VERSION ""

NS_ :

BS_:

BU_:
VAL_TABLE_ VT_PTO_req 1 "Engage_RPTO" 0 "Disengage_RPTO" ;
VAL_TABLE_ VT_MFD_req 1 "FWD_Engaged" 0 "FWD_Disengaged" ;
VAL_TABLE_ VT_FNR 252 "Trans_Forward" 251 "Trans_Park" 223 "Trans_Reverse" 207 "Trans_Neutral_DumpClutch" 125 "Trans_Neutral" 3 "Unknown" ;

BO_ 3221225472 VECTOR__INDEPENDENT_SIG_MSG: 0 Vector__XXX
 SG_ iMeasuredREV_mA_float : 0|11@1+ (1,0) [0|2047] "mA" Vector__XXX
 SG_ iMeasuredFWD_mA_float : 0|11@1+ (1,0) [0|2047] "mA" Vector__XXX

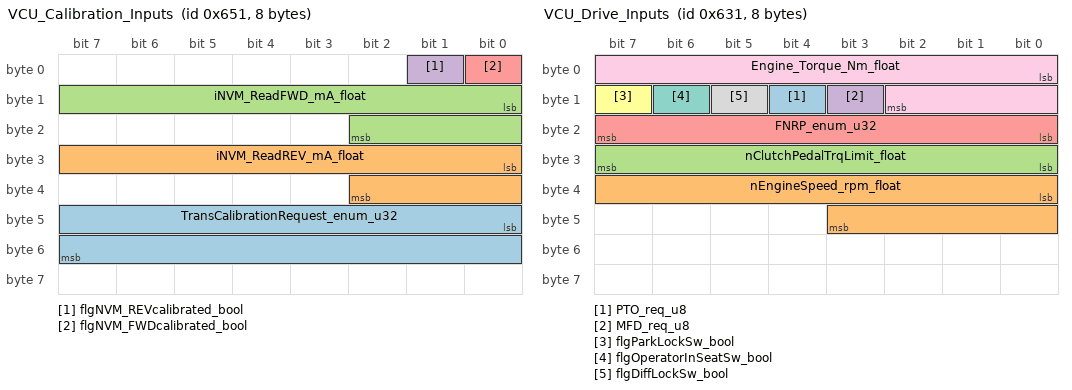
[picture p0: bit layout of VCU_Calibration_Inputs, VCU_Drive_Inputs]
BO_ 1617 VCU_Calibration_Inputs: 8 Vector__XXX
 SG_ TransCalibrationRequest_enum_u32 : 40|16@1+ (1,0) [0|65535] "" Vector__XXX
 SG_ iNVM_ReadREV_mA_float : 24|11@1+ (1,0) [0|2047] "mA" Vector__XXX
 SG_ iNVM_ReadFWD_mA_float : 8|11@1+ (1,0) [0|2047] "mA" Vector__XXX
 SG_ flgNVM_REVcalibrated_bool : 1|1@1+ (1,0) [0|1] "" Vector__XXX
 SG_ flgNVM_FWDcalibrated_bool : 0|1@1+ (1,0) [0|1] "" Vector__XXX

BO_ 1697 VCU_Outputs: 8 Vector__XXX
 SG_ nTransmissionSpeed_rpm_float m0 : 41|13@1+ (1,0) [0|8191] "rpm" Vector__XXX
 SG_ Outputs_mux M : 0|8@1+ (1,0) [0|255] "" Vector__XXX
 SG_ tTransOil_degC_float m0 : 21|8@1+ (1,0) [0|255] "degC" Vector__XXX
 SG_ TransCalibrationStatus_enum_u32 m3 : 32|16@1+ (1,0) [0|65535] "" Vector__XXX
 SG_ TranNonCriticalErrors_u32 m2 : 40|16@1+ (1,0) [0|65535] "" Vector__XXX
 SG_ TranNonCriticalErrors3_u32 m2 : 8|16@1+ (1,0) [0|65535] "" Vector__XXX
 SG_ TranNonCriticalErrors2_u32 m2 : 24|16@1+ (1,0) [0|65535] "" Vector__XXX
 SG_ TranCriticalErrors_u32 m1 : 24|16@1+ (1,0) [0|65535] "" Vector__XXX
 SG_ PTOCriticalErrors_u32 m1 : 40|16@1+ (1,0) [0|65535] "" Vector__XXX
 SG_ pSystemPressure_kpa_float m0 : 29|12@1+ (1,0) [0|4095] "kPa" Vector__XXX
 SG_ nPTOspeed_rpm_float m0 : 8|13@1+ (1,0) [0|8191] "rpm" Vector__XXX
 SG_ MFDCriticalErrors_u32 m1 : 8|16@1+ (1,0) [0|65535] "" Vector__XXX
 SG_ iNVM_WriteREV_mA_float m3 : 21|11@1+ (1,0) [0|2047] "mA" Vector__XXX
 SG_ iNVM_WriteFWD_mA_float m3 : 10|11@1+ (1,0) [0|2047] "mA" Vector__XXX
 SG_ flgNVM_REVready_bool m3 : 9|1@1+ (1,0) [0|1] "" Vector__XXX
 SG_ flgNVM_FWDready_bool m3 : 8|1@1+ (1,0) [0|1] "" Vector__XXX

BO_ 1585 VCU_Drive_Inputs: 8 Vector__XXX
 SG_ PTO_req_u8 : 12|1@1+ (1,0) [0|1] "" Vector__XXX
 SG_ nEngineSpeed_rpm_float : 32|12@1+ (1,0) [0|4095] "rpm" Vector__XXX
 SG_ nClutchPedalTrqLimit_float : 24|8@1- (1,0) [-128|127] "%" Vector__XXX
 SG_ MFD_req_u8 : 11|1@1+ (1,0) [0|1] "" Vector__XXX
 SG_ FNRP_enum_u32 : 16|8@1+ (1,0) [0|255] "" Vector__XXX
 SG_ flgParkLockSw_bool : 15|1@1+ (1,0) [0|1] "" Vector__XXX
 SG_ flgOperatorInSeatSw_bool : 14|1@1+ (1,0) [0|1] "" Vector__XXX
 SG_ flgDiffLockSw_bool : 13|1@1+ (1,0) [0|1] "" Vector__XXX
 SG_ Engine_Torque_Nm_float : 0|11@1+ (1,0) [0|2047] "Nm" Vector__XXX

CM_ BO_ 3221225472 "This is a message for not used signals, created by Vector CANdb++ DBC OLE DB Provider.";
BA_DEF_  "version" STRING ;
BA_DEF_ BO_  "GenMsgSendType" ENUM  "Cyclic","NotUsed","NotUsed","NotUsed","NotUsed","NotUsed","NotUsed","IfActive","NoMsgSendType","NotUsed","vector_leerstring";
BA_DEF_DEF_  "version" "draft_20191030";
BA_DEF_DEF_  "GenMsgSendType" "NoMsgSendType";
BA_ "version" "";
VAL_ 1585 PTO_req_u8 1 "Engage_RPTO" 0 "Disengage_RPTO" ;
VAL_ 1585 MFD_req_u8 1 "FWD_Engaged" 0 "FWD_Disengaged" ;
VAL_ 1585 FNRP_enum_u32 252 "Trans_Forward" 251 "Trans_Park" 223 "Trans_Reverse" 207 "Trans_Neutral_DumpClutch" 125 "Trans_Neutral" 3 "Unknown" ;
